VERSION ""

NS_ :

BS_:

BU_: Car1516_ESP_WS

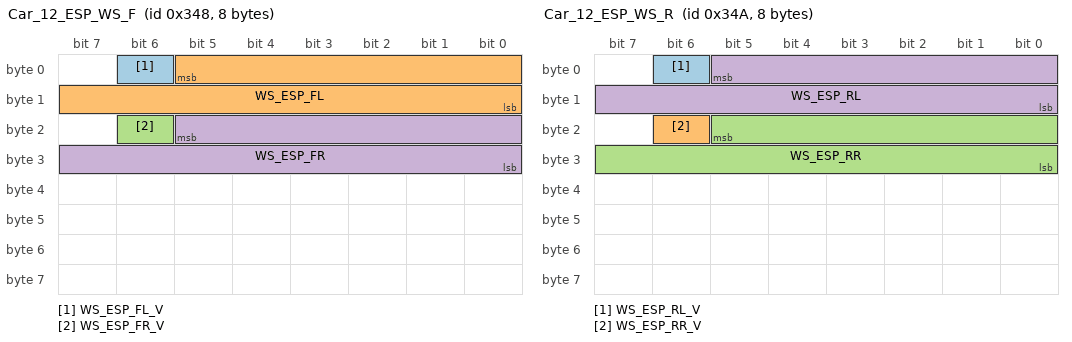
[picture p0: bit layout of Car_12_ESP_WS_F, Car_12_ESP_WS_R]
BO_ 840 Car_12_ESP_WS_F: 8 Vector__XXX
 SG_ WS_ESP_FL_V : 6|1@0+ (1,0) [0|1] "" Vector__XXX
 SG_ WS_ESP_FL : 5|14@0+ (0.0194178,0) [0|318.1218174] "" Vector__XXX
 SG_ WS_ESP_FR_V : 22|1@0+ (1,0) [0|1] "" Vector__XXX
 SG_ WS_ESP_FR : 21|14@0+ (0.0194178,0) [0|318.1218174] "" Vector__XXX

BO_ 842 Car_12_ESP_WS_R: 8 Car1516_ESP_WS
 SG_ WS_ESP_RL_V : 6|1@0+ (1,0) [0|1] "" Vector__XXX
 SG_ WS_ESP_RR_V : 22|1@0+ (1,0) [0|1] "" Vector__XXX
 SG_ WS_ESP_RR : 21|14@0+ (0.0194178,0) [0|318.1218174] "" Vector__XXX
 SG_ WS_ESP_RL : 5|14@0+ (0.0194178,0) [0|318.1218174] "" Vector__XXX
